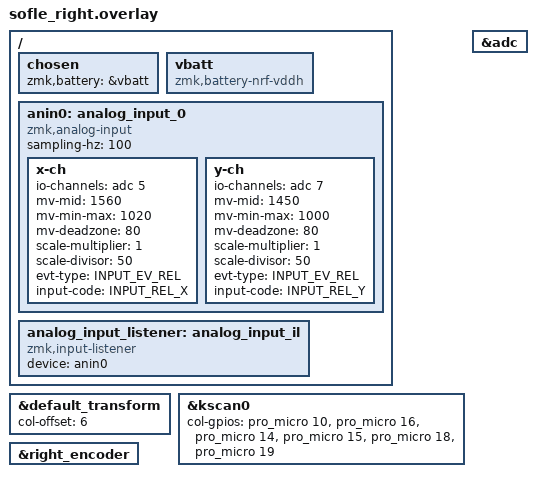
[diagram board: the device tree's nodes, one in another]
/*
 * Copyright (c) 2020 Ryan Cross
 *
 * SPDX-License-Identifier: MIT
 */

#include "sofle.dtsi"
#include <zephyr/dt-bindings/input/input-event-codes.h>

&default_transform {
	col-offset = <6>;
};

&kscan0 {
	col-gpios
		= <&pro_micro 10 GPIO_ACTIVE_HIGH>
		, <&pro_micro 16 GPIO_ACTIVE_HIGH>
		, <&pro_micro 14 GPIO_ACTIVE_HIGH>
		, <&pro_micro 15 GPIO_ACTIVE_HIGH>
		, <&pro_micro 18 GPIO_ACTIVE_HIGH>
		, <&pro_micro 19 GPIO_ACTIVE_HIGH>
		;
};

&right_encoder {
	status = "okay";
};

&adc {
	status = "okay";
};

/ {
	chosen {
		zmk,battery = &vbatt;
	};

	vbatt: vbatt {
		compatible = "zmk,battery-nrf-vddh";
	};

	anin0: analog_input_0 {
		compatible = "zmk,analog-input";
		sampling-hz = <100>;

		x-ch {
			io-channels = <&adc 5>;
			mv-mid = <1560>;
			mv-min-max = <1020>;
			mv-deadzone = <80>;
			scale-multiplier = <1>;
			scale-divisor = <50>;
			evt-type = <INPUT_EV_REL>;
			input-code = <INPUT_REL_X>;
		};

		y-ch {
			io-channels = <&adc 7>;
			mv-mid = <1450>;
			mv-min-max = <1000>;
			mv-deadzone = <80>;
			scale-multiplier = <1>;
			scale-divisor = <50>;
			evt-type = <INPUT_EV_REL>;
			input-code = <INPUT_REL_Y>;
		};
	};

	analog_input_listener: analog_input_il {
		compatible = "zmk,input-listener";
		device = <&anin0>;
	};
};
